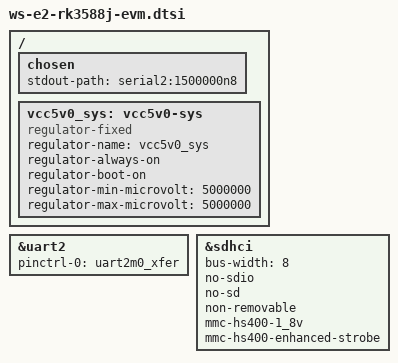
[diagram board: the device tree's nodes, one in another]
// SPDX-License-Identifier: (GPL-2.0+ OR MIT)
/*
 * Minimal first-boot candidate: RK806-1, UART2 M0 and on-module eMMC only.
 * DDR is initialized by the selected Rockchip loader; capacity is intentionally
 * not declared here because the schematic and current prose disagree.
 */

/ {
	chosen {
		stdout-path = "serial2:1500000n8";
	};

	vcc5v0_sys: vcc5v0-sys {
		compatible = "regulator-fixed";
		regulator-name = "vcc5v0_sys";
		regulator-always-on;
		regulator-boot-on;
		regulator-min-microvolt = <5000000>;
		regulator-max-microvolt = <5000000>;
	};
};

&uart2 {
	pinctrl-names = "default";
	pinctrl-0 = <&uart2m0_xfer>;
	status = "okay";
};

&sdhci {
	bus-width = <8>;
	no-sdio;
	no-sd;
	non-removable;
	mmc-hs400-1_8v;
	mmc-hs400-enhanced-strobe;
	status = "okay";
};
